# M4G7 register map
File version: 0.1
Registers are 32-bit, read-write, reset 0x0 unless marked. A register's access mark holds for its fields unless they carry their own. Offsets are from the block's base; [hi:lo] are bit positions; {n}, {i} and the like mark numbered series; 'fields as' and 'values as' point back to an identical list.

## AD — ADC
Base 0x400BA000
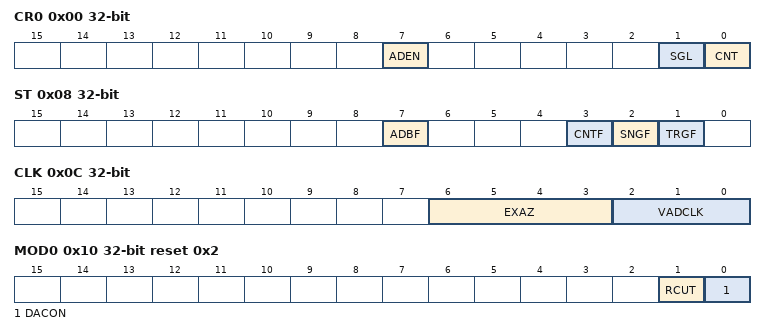
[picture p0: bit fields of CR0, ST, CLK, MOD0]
0x00 CR0 — AD Control Register 0
  [7] ADEN, [1] SGL wo, [0] CNT
0x04 CR1 — AD Control Register 1
  [0] TRGEN
0x08 ST ro — AD Status Register
  [7] ADBF, [3] CNTF, [2] SNGF, [1] TRGF
0x0C CLK — AD Conversion Clock Setting Register
  [6:3] EXAZ, [2:0] VADCLK
0x10 MOD0 reset 0x2 — AD Mode Control Register 0
  [1] RCUT, [0] DACON
0x14 MOD1 reset 0x4000 — AD Mode Control Register 1
0x18 MOD2 — AD Mode Control Register 2
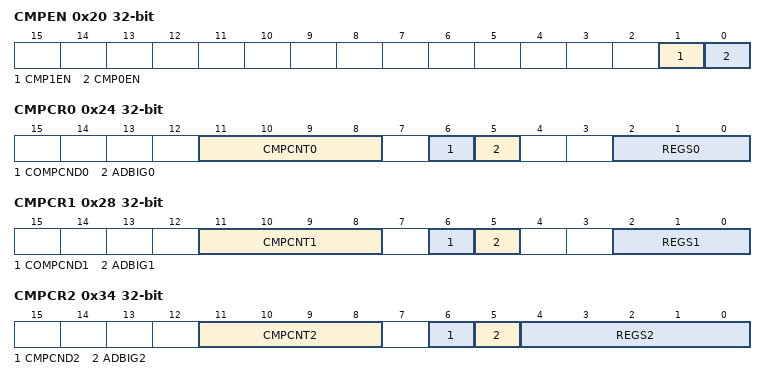
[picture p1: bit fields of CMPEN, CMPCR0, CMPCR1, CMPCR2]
0x20 CMPEN — AD Monitoring interrupt permission register
  [1] CMP1EN, [0] CMP0EN
0x24 CMPCR0 — AD Monitoring Setting Register 0
  [11:8] CMPCNT0, [6] COMPCND0, [5] ADBIG0, [2:0] REGS0
0x28 CMPCR1 — AD Monitoring Setting Register 1
  [11:8] CMPCNT1, [6] COMPCND1, [5] ADBIG1, [2:0] REGS1
0x2C CMP0 — AD Conversion Result Comparison Register 0
  [15:4] ADCMP0
0x30 CMP1 — AD Conversion Result Comparison Register 1
  [15:4] ADCMP1
0x34 CMPCR2 — AD Conversion Monitor Function setting Register 2
  [11:8] CMPCNT2, [6] CMPCND2, [5] ADBIG2, [4:0] REGS2 ro
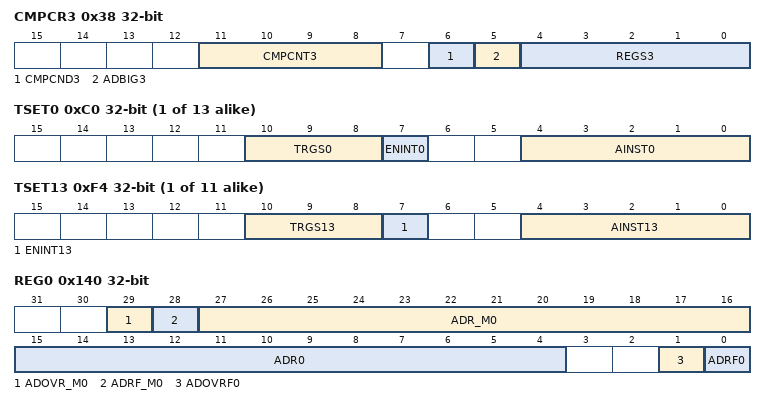
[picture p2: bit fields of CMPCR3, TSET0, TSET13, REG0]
0x38 CMPCR3 — AD Conversion Monitor Function setting Register 3
  [11:8] CMPCNT3, [6] CMPCND3, [5] ADBIG3, [4:0] REGS3 ro
0x3C CMP2 — AD Conversion Result Comparison Register 2
  [15:4] ADCMP2
0x40 CMP3 — AD Conversion Result Comparison Register 3
  [15:4] ADCMP3
0xBC EXAZSEL — AIN sampling period selection register
{0xC0+4i} TSET{i} (i=0..12) — AD General purpose Trigger Program Register {i}
  [10:8] TRGS{i}, [7] ENINT{i}, [4:0] AINST{i}
{0xC0+4i} TSET{i} (i=13..23) — AD General purpose Trigger Program Register 12
  [10:8] TRGS{i}, [7] ENINT{i}, [4:0] AINST{i}
0x140 REG0 ro — AD AD Conversion Result Register 0
  [29] ADOVR_M0, [28] ADRF_M0, [27:16] ADR_M0, [15:4] ADR0, [1] ADOVRF0, [0] ADRF0
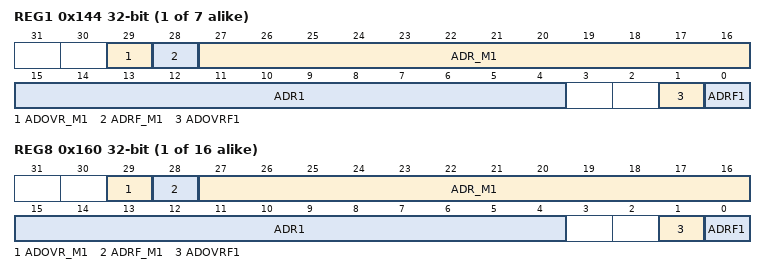
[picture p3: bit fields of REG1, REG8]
{0x140+4i} REG{i} ro (i=1..7) — AD Conversion Result Register {i}
  [29] ADOVR_M{i}, [28] ADRF_M{i}, [27:16] ADR_M{i}, [15:4] ADR{i}, [1] ADOVRF{i}, [0] ADRF{i}
{0x140+4i} REG{i} ro (i=8..23) — AD Conversion Result Register 7
  fields as REG1

## DA0 — Digital analog converter (DAC)
Base 0x400BC800
Same registers: DA1 0x400BC900
0x00 CTL — DAC Control Register
  [0] EN
0x04 REG — DAC output Register
  [7:0] DAC

## T32A0 — 16-bit Timer_Event Counter (TB)
Base 0x400C1000
Same registers: T32A{n} {0x400C1000+0x400*n} (n=1..13)
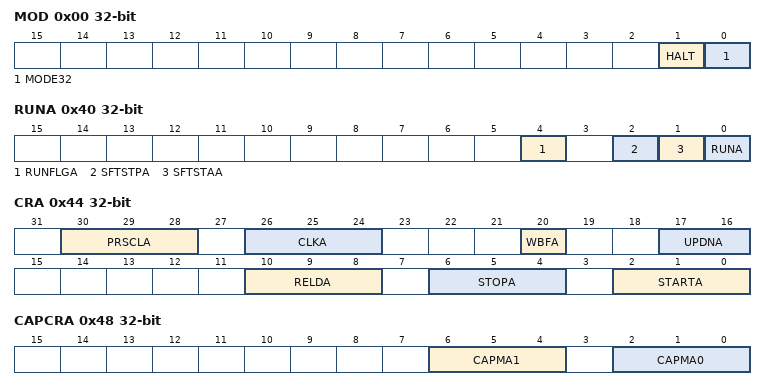
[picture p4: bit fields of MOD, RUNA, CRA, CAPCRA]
0x00 MOD — T32A Mode Register
  [1] HALT, [0] MODE32
0x40 RUNA — T32A Run Register A
  [4] RUNFLGA ro, [2] SFTSTPA wo, [1] SFTSTAA wo, [0] RUNA
0x44 CRA — T32A Control Register A
  [30:28] PRSCLA, [26:24] CLKA, [20] WBFA, [17:16] UPDNA, [10:8] RELDA, [6:4] STOPA, [2:0] STARTA
0x48 CAPCRA — T32A Capture Control Register A
  [6:4] CAPMA1, [2:0] CAPMA0
0x4C OUTCRA0 wo — T32A Output Control Register A0
  [1:0] OCRA
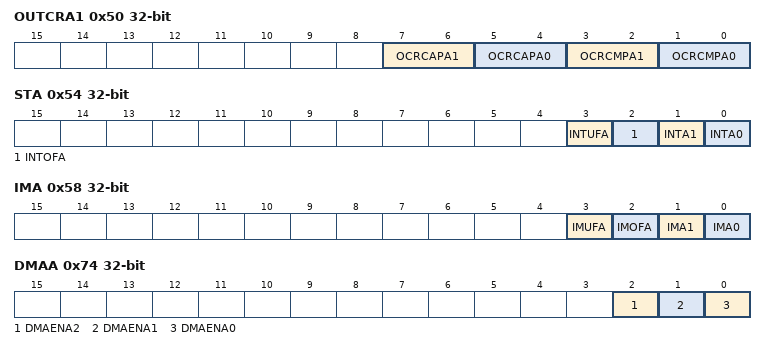
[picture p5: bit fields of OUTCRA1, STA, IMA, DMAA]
0x50 OUTCRA1 — T32A Output Control Register A1
  [7:6] OCRCAPA1, [5:4] OCRCAPA0, [3:2] OCRCMPA1, [1:0] OCRCMPA0
0x54 STA — T32A Status Register A
  [3] INTUFA, [2] INTOFA, [1] INTA1, [0] INTA0
0x58 IMA — T32A Interrupt Mask Register A
  [3] IMUFA, [2] IMOFA, [1] IMA1, [0] IMA0
0x5C TMRA ro — T32A Counter Capture Register A
  [15:0] TMRA
0x60 RELDA — T32A Reload Register A
  [15:0] RELDA
0x64 RGA0 — T32A Timer Register A0
  [15:0] RGA0
0x68 RGA1 — T32A Timer Register A1
  [15:0] RGA1
0x6C CAPA0 ro — T32A Capture Register A0
  [15:0] CAPA0
0x70 CAPA1 ro — T32A Capture Register A1
  [15:0] CAPA1
0x74 DMAA — T32A DMA Request Enable Register A
  [2] DMAENA2, [1] DMAENA1, [0] DMAENA0
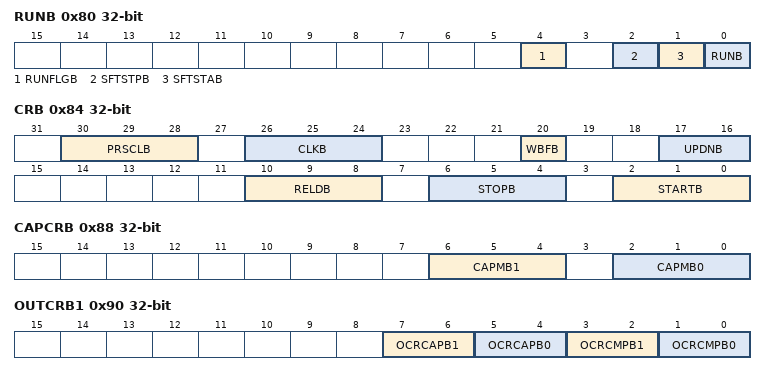
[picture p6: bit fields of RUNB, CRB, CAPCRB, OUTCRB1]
0x80 RUNB — T32A Run Register B
  [4] RUNFLGB ro, [2] SFTSTPB wo, [1] SFTSTAB wo, [0] RUNB
0x84 CRB — T32A Control Register B
  [30:28] PRSCLB, [26:24] CLKB, [20] WBFB, [17:16] UPDNB, [10:8] RELDB, [6:4] STOPB, [2:0] STARTB
0x88 CAPCRB — T32A Capture Control Register B
  [6:4] CAPMB1, [2:0] CAPMB0
0x8C OUTCRB0 wo — T32A Output Control Register B0
  [1:0] OCRB
0x90 OUTCRB1 — T32A Output Control Register B1
  [7:6] OCRCAPB1, [5:4] OCRCAPB0, [3:2] OCRCMPB1, [1:0] OCRCMPB0
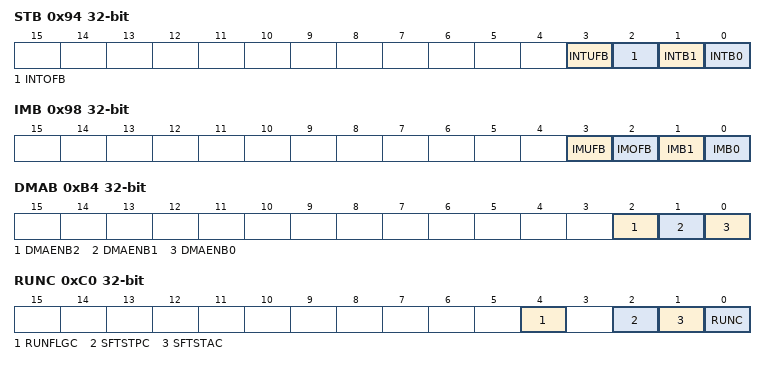
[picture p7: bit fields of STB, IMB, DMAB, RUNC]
0x94 STB — T32A Status Register B
  [3] INTUFB, [2] INTOFB, [1] INTB1, [0] INTB0
0x98 IMB — T32A Interrupt Mask Register B
  [3] IMUFB, [2] IMOFB, [1] IMB1, [0] IMB0
0x9C TMRB ro — T32A Counter Capture Register B
  [15:0] TMRB
0xA0 RELDB — T32A Reload Register B
  [15:0] RELDB
0xA4 RGB0 — T32A Timer Register B0
  [15:0] RGB0
0xA8 RGB1 — T32A Timer Register B1
  [15:0] RGB1
0xAC CAPB0 ro — T32A Capture Register B0
  [15:0] CAPB0
0xB0 CAPB1 ro — T32A Capture Register B1
  [15:0] CAPB1
0xB4 DMAB — T32A DMA Request Enable Register B
  [2] DMAENB2, [1] DMAENB1, [0] DMAENB0
0xC0 RUNC — T32A Run Register C
  [4] RUNFLGC ro, [2] SFTSTPC wo, [1] SFTSTAC wo, [0] RUNC
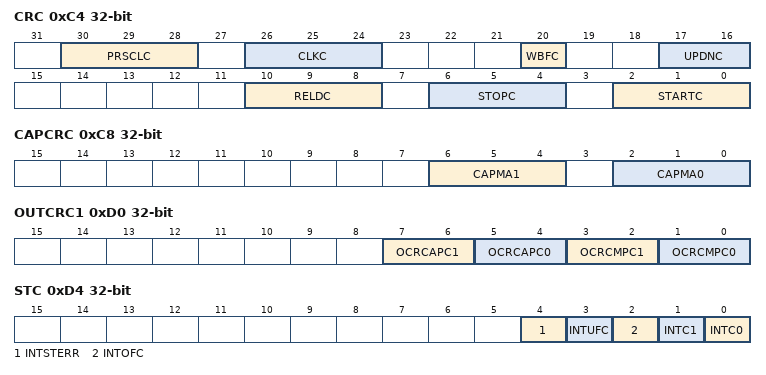
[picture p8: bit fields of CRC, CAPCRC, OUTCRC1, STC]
0xC4 CRC — T32A Control Register C
  [30:28] PRSCLC, [26:24] CLKC, [20] WBFC, [17:16] UPDNC, [10:8] RELDC, [6:4] STOPC, [2:0] STARTC
0xC8 CAPCRC — T32A Capture Control Register C
  [6:4] CAPMA1, [2:0] CAPMA0
0xCC OUTCRC0 wo — T32A Output Control Register C0
  [1:0] OCRC
0xD0 OUTCRC1 — T32A Output Control Register C1
  [7:6] OCRCAPC1, [5:4] OCRCAPC0, [3:2] OCRCMPC1, [1:0] OCRCMPC0
0xD4 STC — T32A Status Register C
  [4] INTSTERR, [3] INTUFC, [2] INTOFC, [1] INTC1, [0] INTC0
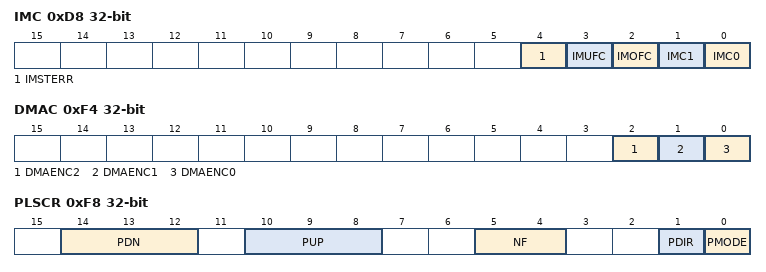
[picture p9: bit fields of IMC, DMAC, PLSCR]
0xD8 IMC — T32A Interrupt Mask Register C
  [4] IMSTERR, [3] IMUFC, [2] IMOFC, [1] IMC1, [0] IMC0
0xDC TMRC ro — T32A Counter Capture Register C
0xE0 RELDC — T32A Reload Register C
0xE4 RGC0 — T32A Timer Register C0
0xE8 RGC1 — T32A Timer Register C1
0xEC CAPC0 ro — T32A Capture Register C0
0xF0 CAPC1 ro — T32A Capture Register C1
0xF4 DMAC — T32A DMA Request Enable Register C
  [2] DMAENC2, [1] DMAENC1, [0] DMAENC0
0xF8 PLSCR — T32A Pulse Count Control Register
  [14:12] PDN, [10:8] PUP, [5:4] NF, [1] PDIR, [0] PMODE
